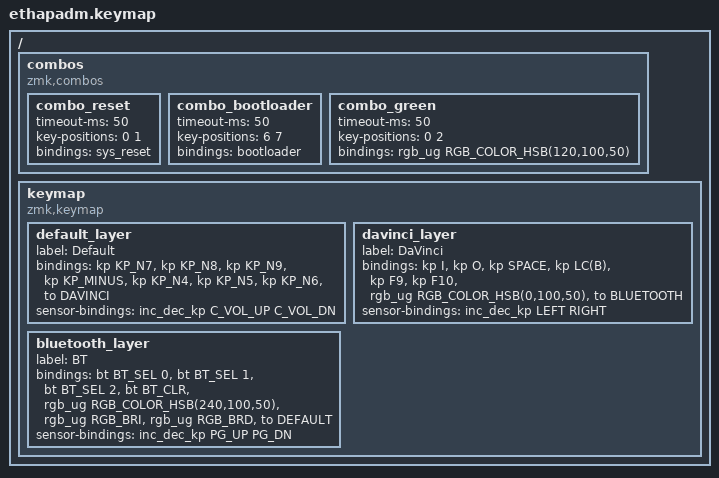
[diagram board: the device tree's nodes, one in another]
/*
 * Copyright (c) 2026 The ZMK Contributors
 *
 * SPDX-License-Identifier: MIT
 */

#include <behaviors.dtsi>
#include <dt-bindings/zmk/keys.h>
#include <dt-bindings/zmk/bt.h>
#include <dt-bindings/zmk/rgb.h>

#define DEFAULT   0
#define DAVINCI   1
#define BLUETOOTH 2

/ {
    combos {
        compatible = "zmk,combos";
        
        combo_reset {
            timeout-ms = <50>;
            key-positions = <0 1>;
            bindings = <&sys_reset>;
        };
        
        combo_bootloader {
            timeout-ms = <50>;
            key-positions = <6 7>;
            bindings = <&bootloader>;
        };

        combo_green {
            timeout-ms = <50>;
            key-positions = <0 2>;
            bindings = <&rgb_ug RGB_COLOR_HSB(120,100,50)>;
        };
    };

    keymap {
        compatible = "zmk,keymap";

        default_layer {
            label = "Default";
            bindings = <
                &kp KP_N7  &kp KP_N8  &kp KP_N9  &kp KP_MINUS  &kp KP_N4  &kp KP_N5  &kp KP_N6  &to DAVINCI
            >;
            
            sensor-bindings = <&inc_dec_kp C_VOL_UP C_VOL_DN>;
        };

        davinci_layer {
            label = "DaVinci";
            bindings = <
                &kp I  &kp O  &kp SPACE  &kp LC(B)  &kp F9  &kp F10  &rgb_ug RGB_COLOR_HSB(0,100,50)  &to BLUETOOTH
            >;
            
            sensor-bindings = <&inc_dec_kp LEFT RIGHT>;
        };

        bluetooth_layer {
            label = "BT";
            bindings = <
                &bt BT_SEL 0  &bt BT_SEL 1  &bt BT_SEL 2  &bt BT_CLR  &rgb_ug RGB_COLOR_HSB(240,100,50)  &rgb_ug RGB_BRI  &rgb_ug RGB_BRD  &to DEFAULT
            >;
            
            sensor-bindings = <&inc_dec_kp PG_UP PG_DN>;
        };
    };
};
